# FM33FG0XXA register map
File version: 1.0
CPU: SC000 r1p0, little endian, MPU, no FPU, 3 interrupt priority bits
Registers are 32-bit, read-only, reset 0x0 unless marked. A register's access mark holds for its fields unless they carry their own. Offsets are from the block's base; [hi:lo] are bit positions; {n}, {i} and the like mark numbered series.

## SENT0 — SENT0 module information
Base 0x4001B000
Same registers: SENT1 0x4001B400
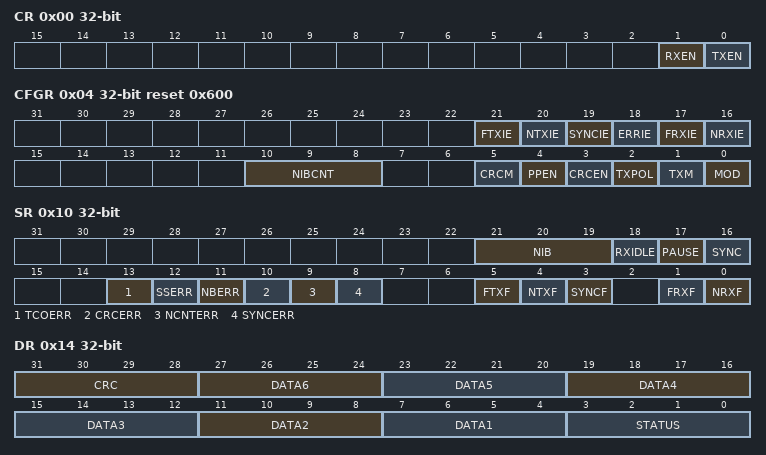
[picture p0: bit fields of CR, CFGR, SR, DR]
0x00 CR rw — SENT0Control Register
  [1] RXEN — RXEN field description
  [0] TXEN — TXEN field description
0x04 CFGR rw reset 0x600 — SENT0 Configure Register
  [21] FTXIE — FTXIE field description
  [20] NTXIE — NTXIE field description
  [19] SYNCIE — SYNCIE field description
  [18] ERRIE — ERRIE field description
  [17] FRXIE — FRXIE field description
  [16] NRXIE — NRXIE field description
  [10:8] NIBCNT — NIBCNT field description
  [5] CRCM — CRCM field description
  [4] PPEN — PPEN field description
  [3] CRCEN — CRCEN field description
  [2] TXPOL — TXPOL field description
  [1] TXM — TXM field description
  [0] MOD — MOD field description
0x08 PSR rw — SENT0 Prescaler Register
  [15:0] PRESCALER — PRESCALER field description
0x0C FTR rw reset 0x4 — SENT0 Frame Length Register
  [11:0] FRAMETIME — FRAMETIME field description
0x10 SR access per field — SENT0Status and Flag Register
  [21:19] NIB ro — NIB field description
  [18] RXIDLE ro — RXIDLE field description
  [17] PAUSE ro — PAUSE field description
  [16] SYNC ro — SYNC field description
  [13] TCOERR rw — TCOERR field description
  [12] SSERR rw — SSERR field description
  [11] NBERR rw — NBERR field description
  [10] CRCERR rw — CRCERR field description
  [9] NCNTERR rw — NCNTERR field description
  [8] SYNCERR rw — SYNCERR field description
  [5] FTXF rw — FTXF field description
  [4] NTXF rw — NTXF field description
  [3] SYNCF rw — SYNCF field description
  [1] FRXF rw — FRXF field description
  [0] NRXF rw — NRXF field description
0x14 DR rw — SENT0 Data Register
  [31:28] CRC — CRC field description
  [4n+3:4n] DATA{n} (n=1..6) — DATA{n} field description
  [3:0] STATUS — STATUS field description
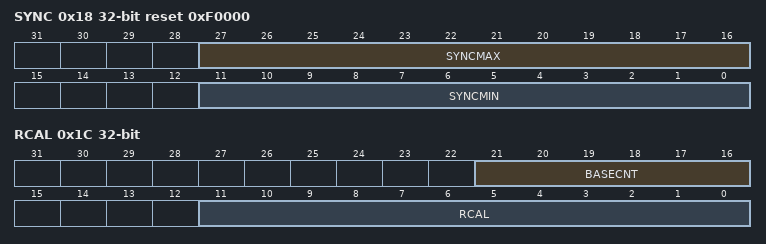
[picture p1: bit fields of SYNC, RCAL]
0x18 SYNC rw reset 0xF0000 — SENT0 Synchronous Pluse Diagnosis Register
  [27:16] SYNCMAX — SYNCMAX field description
  [11:0] SYNCMIN — SYNCMIN field description
0x1C RCAL — SENT0 Synchronous Calibration Register
  [21:16] BASECNT — BASECNT field description
  [11:0] RCAL — RCAL field description

## DMA — DMA module information
Base 0x40000400
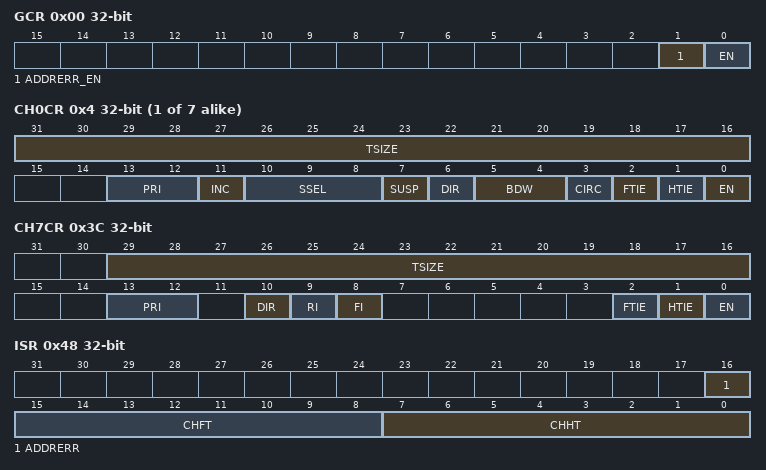
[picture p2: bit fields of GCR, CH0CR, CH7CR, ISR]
0x00 GCR rw — DMA Global Control Register
  [1] ADDRERR_EN — ADDRERR_EN field description
  [0] EN — EN field description
{0x4+8i} CH{i}CR rw (i=0..6) — Channel {i} Control Register
  [31:16] TSIZE — TSIZE field description
  [13:12] PRI — PRI field description
  [11] INC — INC field description
  [10:8] SSEL — SSEL field description
  [7] SUSP — SUSP field description
  [6] DIR — DIR field description
  [5:4] BDW — BDW field description
  [3] CIRC — CIRC field description
  [2] FTIE — FTIE field description
  [1] HTIE — HTIE field description
  [0] EN — EN field description
{0x8+8i} CH{i}MAR rw (i=0..6) — Channel {i} Memory Address Register
  [31:0] MEMAD — MEMAD field description
0x3C CH7CR rw — Channel 7 Control Register
  [29:16] TSIZE — TSIZE field description
  [13:12] PRI — PRI field description
  [10] DIR — DIR field description
  [9] RI — RI field description
  [8] FI — FI field description
  [2] FTIE — FTIE field description
  [1] HTIE — HTIE field description
  [0] EN — EN field description
0x40 CH7FLSAD rw — Channel 7 Flash Address Register
  [16:0] FLSAD — FLSAD field description
0x44 CH7RAMAD rw — Channel 7 RAM Address Register
  [15:0] RAMAD — RAMAD field description
0x48 ISR rw — DMA Interrupt Status Register
  [16] ADDRERR — ADDRERR field description
  [15:8] CHFT — CHFT field description
  [7:0] CHHT — CHHT field description

## CRC — CRC module information
Base 0x40010000
0x00 DR rw — CRC Data Register
  [31:0] DR — DR field description
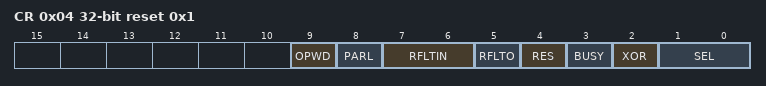
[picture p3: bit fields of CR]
0x04 CR access per field reset 0x1 — CRC Control Register
  [9] OPWD rw — OPWD field description
  [8] PARL rw — PARL field description
  [7:6] RFLTIN rw — RFLTIN field description
  [5] RFLTO rw — RFLTO field description
  [4] RES ro — RES field description
  [3] BUSY ro — BUSY field description
  [2] XOR rw — XOR field description
  [1:0] SEL rw — SEL field description
0x08 LFSR rw — CRC Linear Feedback Shift Register
  [31:0] LFSR — LFSR field description
0x0C XOR rw — CRC output XOR Register
  [31:0] XOR — XOR field description
0x1C POLY rw — CRC Polynominal Register
  [31:0] POLY — POLY field description
